AUTOSAR XML (schema 4-2-2)
package /EB/SoftwareComponents
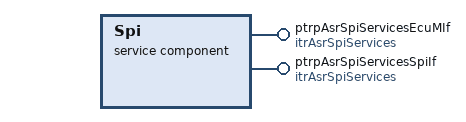
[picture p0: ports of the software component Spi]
  service sw component type Spi: category=ASR_Interfaces
    provide port ptrpAsrSpiServicesEcuMIf: provided-interface=itrAsrSpiServices
    provide port ptrpAsrSpiServicesSpiIf: provided-interface=itrAsrSpiServices
    behavior Spi_IB: handle-termination-and-restart=NO-SUPPORT
      5 x runnable:
        Spi_GetStatus: external-triggering-point=ptrpAsrSpiServicesSpiIf
        Spi_ReadIB: external-triggering-point=ptrpAsrSpiServicesSpiIf.Spi_ReadIB
        Spi_SetAsyncMode: external-triggering-point=ptrpAsrSpiServicesSpiIf
        Spi_SyncTransmit: external-triggering-point=ptrpAsrSpiServicesSpiIf.Spi_SyncTransmit
        Spi_WriteIB: external-triggering-point=ptrpAsrSpiServicesSpiIf.Spi_WriteIB
package /EB/TriggerInterfaces
  trigger interface itrAsrSpiServices
    4 x trigger, all with trigger-period={cse-code=1000, cse-code-factor=0}:
      Spi_Init
      Spi_ReadIB
      Spi_SyncTransmit
      Spi_WriteIB
